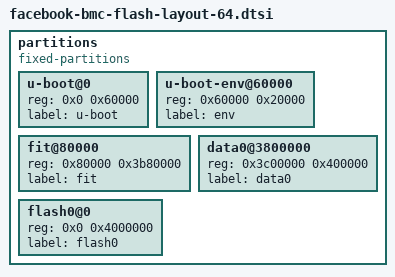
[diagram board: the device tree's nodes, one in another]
// SPDX-License-Identifier: GPL-2.0+
// Copyright (c) 2020 Facebook Inc.

partitions {
	compatible = "fixed-partitions";
	#address-cells = <1>;
	#size-cells = <1>;

	/*
	 * u-boot partition: 384KB.
	 */
	u-boot@0 {
		reg = <0x0 0x60000>;
		label = "u-boot";
	};

	/*
	 * u-boot environment variables: 128KB.
	 */
	u-boot-env@60000 {
		reg = <0x60000 0x20000>;
		label = "env";
	};

	/*
	 * FIT image: 59.5 MB.
	 */
	fit@80000 {
		reg = <0x80000 0x3b80000>;
		label = "fit";
	};

	/*
	 * "data0" partition (4MB) is used by Facebook BMC platforms as
	 * persistent data store.
	 */
	data0@3800000 {
		reg = <0x3c00000 0x400000>;
		label = "data0";
	};

	/*
	 * Although the master partition can be created by enabling
	 * MTD_PARTITIONED_MASTER option, below "flash0" partition is
	 * explicitly created to avoid breaking legacy applications.
	 */
	flash0@0 {
		reg = <0x0 0x4000000>;
		label = "flash0";
	};
};
